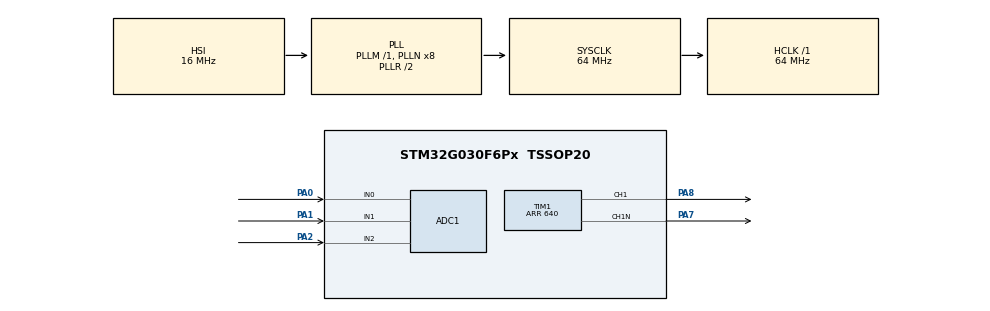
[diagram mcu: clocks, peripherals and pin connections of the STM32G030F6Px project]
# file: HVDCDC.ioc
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ADC1.Channel-4\#ChannelRegularConversion=ADC_CHANNEL_1
ADC1.Channel-5\#ChannelRegularConversion=ADC_CHANNEL_2
ADC1.Channel-6\#ChannelRegularConversion=ADC_CHANNEL_TEMPSENSOR
ADC1.ChannelTS=ADC_CHANNEL_TEMPSENSOR
ADC1.DMAContinuousRequests=ENABLE
ADC1.EOCSelection=ADC_EOC_SEQ_CONV
ADC1.ExternalTrigConv=ADC_EXTERNALTRIG_T1_CC4
ADC1.NbrOfConversion=4
ADC1.NbrOfConversionFlag=1
ADC1.Rank-4\#ChannelRegularConversion=2
ADC1.Rank-5\#ChannelRegularConversion=3
ADC1.Rank-6\#ChannelRegularConversion=4
ADC1.SamplingTime-4\#ChannelRegularConversion=ADC_SAMPLINGTIME_COMMON_1
ADC1.SamplingTime-5\#ChannelRegularConversion=ADC_SAMPLINGTIME_COMMON_1
ADC1.SamplingTime-6\#ChannelRegularConversion=ADC_SAMPLINGTIME_COMMON_1
ADC1.SamplingTimeCommon1=ADC_SAMPLETIME_7CYCLES_5
ADC1.SamplingTimeCommon2=ADC_SAMPLETIME_12CYCLES_5
ADC1.SelectedChannel=ADC_CHANNEL_0|ADC_CHANNEL_1|ADC_CHANNEL_2|ADC_CHANNEL_TEMPSENSOR
ADC1.master=1
Dma.ADC1.0.Direction=DMA_PERIPH_TO_MEMORY
Dma.ADC1.0.EventEnable=ENABLE
Dma.ADC1.0.Instance=DMA1_Channel1
Dma.ADC1.0.MemDataAlignment=DMA_MDATAALIGN_HALFWORD
Dma.ADC1.0.MemInc=DMA_MINC_ENABLE
Dma.ADC1.0.Mode=DMA_CIRCULAR
Dma.ADC1.0.PeriphDataAlignment=DMA_PDATAALIGN_HALFWORD
Dma.ADC1.0.PeriphInc=DMA_PINC_DISABLE
Dma.ADC1.0.Polarity=HAL_DMAMUX_REQ_GEN_RISING
Dma.ADC1.0.Priority=DMA_PRIORITY_LOW
Dma.ADC1.0.RequestNumber=1
Dma.ADC1.0.SignalID=NONE
Dma.ADC1.0.SyncEnable=DISABLE
Dma.ADC1.0.SyncPolarity=HAL_DMAMUX_SYNC_NO_EVENT
Dma.ADC1.0.SyncRequestNumber=1
Dma.ADC1.0.SyncSignalID=NONE
Dma.Request0=ADC1
Mcu.Family=STM32G0
Mcu.Name=STM32G030F6Px
Mcu.Package=TSSOP20
NVIC.ADC1_IRQn=true\:0\:0\:false\:false\:true\:true\:true\:true
PA0.Mode=IN0
PA0.Signal=ADC1_IN0
PA1.Mode=IN1
PA1.Signal=ADC1_IN1
PA13.Mode=Serial_Wire
PA13.Signal=SYS_SWDIO
PA14-BOOT0.Mode=Serial_Wire
PA14-BOOT0.Signal=SYS_SWCLK
PA14-BOOT0__PA15.StandardMode=true
PA2.Mode=IN2
PA2.Signal=ADC1_IN2
PA7.Mode=PWM Generation1 CH1 CH1N
PA7.Signal=TIM1_CH1N
PA8.Signal=S_TIM1_CH1
PB0__PB1__PB2__PA8.StandardMode=true
PB3__PB4__PB5__PB6.StandardMode=true
PB7__PB8.StandardMode=true
PC14-OSC32_IN\ (PC14)__PB9.StandardMode=true
ProjectManager.HeapSize=0x200
ProjectManager.StackSize=0x400
ProjectManager.TargetToolchain=STM32CubeIDE
RCC.ADCFreq_Value=64000000
RCC.AHBFreq_Value=64000000
RCC.CortexFreq_Value=64000000
RCC.EXTERNAL_CLOCK_VALUE=12288000
RCC.HCLKFreq_Value=64000000
RCC.HSE_VALUE=8000000
RCC.HSI_VALUE=16000000
RCC.LSE_VALUE=32768
RCC.SYSCLKFreq_VALUE=64000000
RCC.SYSCLKSource=RCC_SYSCLKSOURCE_PLLCLK
RCC.VCOOutputFreq_Value=128000000
SH.S_TIM1_CH1.0=TIM1_CH1,PWM Generation1 CH1 CH1N
TIM1.Channel-PWM\ Generation1\ CH1\ CH1N=TIM_CHANNEL_1
TIM1.Channel-PWM\ Generation4\ No\ Output=TIM_CHANNEL_4
TIM1.DeadTime=20
TIM1.OffStateIDLEMode=TIM_OSSI_DISABLE
TIM1.Period=640
TIM1.Pulse-PWM\ Generation4\ No\ Output=500
TIM1.TIM_MasterOutputTrigger=TIM_TRGO_OC4REF
VP_ADC1_TempSens_Input.Mode=IN-TempSens
VP_TIM1_VS_no_output4.Mode=PWM Generation4 No Output
board=custom

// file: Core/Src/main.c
/* USER CODE BEGIN Header */
/**
  ******************************************************************************
  * @file           : main.c
  * @brief          : Main program body
  ******************************************************************************
  * @attention
  *
  * Copyright (c) 2022 STMicroelectronics.
  * All rights reserved.
  *
  * This software is licensed under terms that can be found in the LICENSE file
  * in the root directory of this software component.
  * If no LICENSE file comes with this software, it is provided AS-IS.
  *
  ******************************************************************************
  */
/* USER CODE END Header */
#include "main.h"
#include "HVDCDC.h"

ADC_HandleTypeDef hadc1;
DMA_HandleTypeDef hdma_adc1;

TIM_HandleTypeDef htim1;

/* USER CODE BEGIN PV */
uint16_t ADC_Buffer[4];
/* USER CODE END PV */

void SystemClock_Config(void);
static void MX_GPIO_Init(void);
static void MX_DMA_Init(void);
static void MX_ADC1_Init(void);
static void MX_TIM1_Init(void);

/* USER CODE BEGIN 0 */
extern uint32_t Converted_ADC[4];

/* USER CODE END 0 */

int main(void)
{

  /* MCU Configuration--------------------------------------------------------*/

  /* Reset of all peripherals, Initializes the Flash interface and the Systick. */
  HAL_Init();

  /* Configure the system clock */
  SystemClock_Config();

  /* Initialize all configured peripherals */
  MX_GPIO_Init();
  MX_DMA_Init();
  MX_ADC1_Init();
  MX_TIM1_Init();
  /* USER CODE BEGIN 2 */
  HAL_ADCEx_Calibration_Start(&hadc1);
  HAL_Delay(5);
  HAL_ADC_Start_DMA(&hadc1, ADC_Buffer, 4);
HAL_TIM_PWM_Start(&htim1, TIM_CHANNEL_1);
HAL_TIMEx_PWMN_Start(&htim1, TIM_CHANNEL_1);
HAL_TIM_PWM_Start(&htim1, TIM_CHANNEL_4);
__HAL_ADC_ENABLE_IT(&hadc1, ADC_IT_EOS);

  /* USER CODE END 2 */

  /* Infinite loop */
  /* USER CODE BEGIN WHILE */
  while (1)
  {
whileoneloop();
    /* USER CODE END WHILE */

  }
}

void SystemClock_Config(void)
{
  RCC_OscInitTypeDef RCC_OscInitStruct = {0};
  RCC_ClkInitTypeDef RCC_ClkInitStruct = {0};

  /** Configure the main internal regulator output voltage
  */
  HAL_PWREx_ControlVoltageScaling(PWR_REGULATOR_VOLTAGE_SCALE1);

  /** Initializes the RCC Oscillators according to the specified parameters
  * in the RCC_OscInitTypeDef structure.
  */
  RCC_OscInitStruct.OscillatorType = RCC_OSCILLATORTYPE_HSI;
  RCC_OscInitStruct.HSIState = RCC_HSI_ON;
  RCC_OscInitStruct.HSIDiv = RCC_HSI_DIV1;
  RCC_OscInitStruct.HSICalibrationValue = RCC_HSICALIBRATION_DEFAULT;
  RCC_OscInitStruct.PLL.PLLState = RCC_PLL_ON;
  RCC_OscInitStruct.PLL.PLLSource = RCC_PLLSOURCE_HSI;
  RCC_OscInitStruct.PLL.PLLM = RCC_PLLM_DIV1;
  RCC_OscInitStruct.PLL.PLLN = 8;
  RCC_OscInitStruct.PLL.PLLP = RCC_PLLP_DIV2;
  RCC_OscInitStruct.PLL.PLLR = RCC_PLLR_DIV2;
  if (HAL_RCC_OscConfig(&RCC_OscInitStruct) != HAL_OK)
  {
    Error_Handler();
  }

  /** Initializes the CPU, AHB and APB buses clocks
  */
  RCC_ClkInitStruct.ClockType = RCC_CLOCKTYPE_HCLK|RCC_CLOCKTYPE_SYSCLK
                              |RCC_CLOCKTYPE_PCLK1;
  RCC_ClkInitStruct.SYSCLKSource = RCC_SYSCLKSOURCE_PLLCLK;
  RCC_ClkInitStruct.AHBCLKDivider = RCC_SYSCLK_DIV1;
  RCC_ClkInitStruct.APB1CLKDivider = RCC_HCLK_DIV1;

  if (HAL_RCC_ClockConfig(&RCC_ClkInitStruct, FLASH_LATENCY_2) != HAL_OK)
  {
    Error_Handler();
  }
}

static void MX_ADC1_Init(void)
{

  ADC_ChannelConfTypeDef sConfig = {0};

  /** Configure the global features of the ADC (Clock, Resolution, Data Alignment and number of conversion)
  */
  hadc1.Instance = ADC1;
  hadc1.Init.ClockPrescaler = ADC_CLOCK_SYNC_PCLK_DIV2;
  hadc1.Init.Resolution = ADC_RESOLUTION_12B;
  hadc1.Init.DataAlign = ADC_DATAALIGN_RIGHT;
  hadc1.Init.ScanConvMode = ADC_SCAN_ENABLE;
  hadc1.Init.EOCSelection = ADC_EOC_SEQ_CONV;
  hadc1.Init.LowPowerAutoWait = DISABLE;
  hadc1.Init.LowPowerAutoPowerOff = DISABLE;
  hadc1.Init.ContinuousConvMode = DISABLE;
  hadc1.Init.NbrOfConversion = 4;
  hadc1.Init.DiscontinuousConvMode = DISABLE;
  hadc1.Init.ExternalTrigConv = ADC_EXTERNALTRIG_T1_CC4;
  hadc1.Init.ExternalTrigConvEdge = ADC_EXTERNALTRIGCONVEDGE_RISING;
  hadc1.Init.DMAContinuousRequests = ENABLE;
  hadc1.Init.Overrun = ADC_OVR_DATA_PRESERVED;
  hadc1.Init.SamplingTimeCommon1 = ADC_SAMPLETIME_7CYCLES_5;
  hadc1.Init.SamplingTimeCommon2 = ADC_SAMPLETIME_12CYCLES_5;
  hadc1.Init.OversamplingMode = DISABLE;
  hadc1.Init.TriggerFrequencyMode = ADC_TRIGGER_FREQ_HIGH;
  if (HAL_ADC_Init(&hadc1) != HAL_OK)
  {
    Error_Handler();
  }

  /** Configure Regular Channel
  */
  sConfig.Channel = ADC_CHANNEL_1;
  sConfig.Rank = ADC_REGULAR_RANK_2;
  sConfig.SamplingTime = ADC_SAMPLINGTIME_COMMON_1;
  if (HAL_ADC_ConfigChannel(&hadc1, &sConfig) != HAL_OK)
  {
    Error_Handler();
  }

  /** Configure Regular Channel
  */
  sConfig.Channel = ADC_CHANNEL_2;
  sConfig.Rank = ADC_REGULAR_RANK_3;
  if (HAL_ADC_ConfigChannel(&hadc1, &sConfig) != HAL_OK)
  {
    Error_Handler();
  }

  /** Configure Regular Channel
  */
  sConfig.Channel = ADC_CHANNEL_TEMPSENSOR;
  sConfig.Rank = ADC_REGULAR_RANK_4;
  if (HAL_ADC_ConfigChannel(&hadc1, &sConfig) != HAL_OK)
  {
    Error_Handler();
  }

}

static void MX_TIM1_Init(void)
{

  TIM_MasterConfigTypeDef sMasterConfig = {0};
  TIM_OC_InitTypeDef sConfigOC = {0};
  TIM_BreakDeadTimeConfigTypeDef sBreakDeadTimeConfig = {0};

  htim1.Instance = TIM1;
  htim1.Init.Prescaler = 0;
  htim1.Init.CounterMode = TIM_COUNTERMODE_UP;
  htim1.Init.Period = 640;
  htim1.Init.ClockDivision = TIM_CLOCKDIVISION_DIV1;
  htim1.Init.RepetitionCounter = 0;
  htim1.Init.AutoReloadPreload = TIM_AUTORELOAD_PRELOAD_DISABLE;
  if (HAL_TIM_PWM_Init(&htim1) != HAL_OK)
  {
    Error_Handler();
  }
  sMasterConfig.MasterOutputTrigger = TIM_TRGO_OC4REF;
  sMasterConfig.MasterOutputTrigger2 = TIM_TRGO2_RESET;
  sMasterConfig.MasterSlaveMode = TIM_MASTERSLAVEMODE_DISABLE;
  if (HAL_TIMEx_MasterConfigSynchronization(&htim1, &sMasterConfig) != HAL_OK)
  {
    Error_Handler();
  }
  sConfigOC.OCMode = TIM_OCMODE_PWM1;
  sConfigOC.Pulse = 0;
  sConfigOC.OCPolarity = TIM_OCPOLARITY_HIGH;
  sConfigOC.OCNPolarity = TIM_OCNPOLARITY_HIGH;
  sConfigOC.OCFastMode = TIM_OCFAST_DISABLE;
  sConfigOC.OCIdleState = TIM_OCIDLESTATE_RESET;
  sConfigOC.OCNIdleState = TIM_OCNIDLESTATE_RESET;
  if (HAL_TIM_PWM_ConfigChannel(&htim1, &sConfigOC, TIM_CHANNEL_1) != HAL_OK)
  {
    Error_Handler();
  }
  sConfigOC.Pulse = 500;
  if (HAL_TIM_PWM_ConfigChannel(&htim1, &sConfigOC, TIM_CHANNEL_4) != HAL_OK)
  {
    Error_Handler();
  }
  sBreakDeadTimeConfig.OffStateRunMode = TIM_OSSR_DISABLE;
  sBreakDeadTimeConfig.OffStateIDLEMode = TIM_OSSI_DISABLE;
  sBreakDeadTimeConfig.LockLevel = TIM_LOCKLEVEL_OFF;
  sBreakDeadTimeConfig.DeadTime = 20;
  sBreakDeadTimeConfig.BreakState = TIM_BREAK_DISABLE;
  sBreakDeadTimeConfig.BreakPolarity = TIM_BREAKPOLARITY_HIGH;
  sBreakDeadTimeConfig.BreakFilter = 0;
  sBreakDeadTimeConfig.BreakAFMode = TIM_BREAK_AFMODE_INPUT;
  sBreakDeadTimeConfig.Break2State = TIM_BREAK2_DISABLE;
  sBreakDeadTimeConfig.Break2Polarity = TIM_BREAK2POLARITY_HIGH;
  sBreakDeadTimeConfig.Break2Filter = 0;
  sBreakDeadTimeConfig.Break2AFMode = TIM_BREAK_AFMODE_INPUT;
  sBreakDeadTimeConfig.AutomaticOutput = TIM_AUTOMATICOUTPUT_DISABLE;
  if (HAL_TIMEx_ConfigBreakDeadTime(&htim1, &sBreakDeadTimeConfig) != HAL_OK)
  {
    Error_Handler();
  }
  HAL_TIM_MspPostInit(&htim1);

}

static void MX_DMA_Init(void)
{

  /* DMA controller clock enable */
  __HAL_RCC_DMA1_CLK_ENABLE();

}

static void MX_GPIO_Init(void)
{

  /* GPIO Ports Clock Enable */
  __HAL_RCC_GPIOA_CLK_ENABLE();

}

void Error_Handler(void)
{
  __disable_irq();
  while (1)
  {
  }
}
